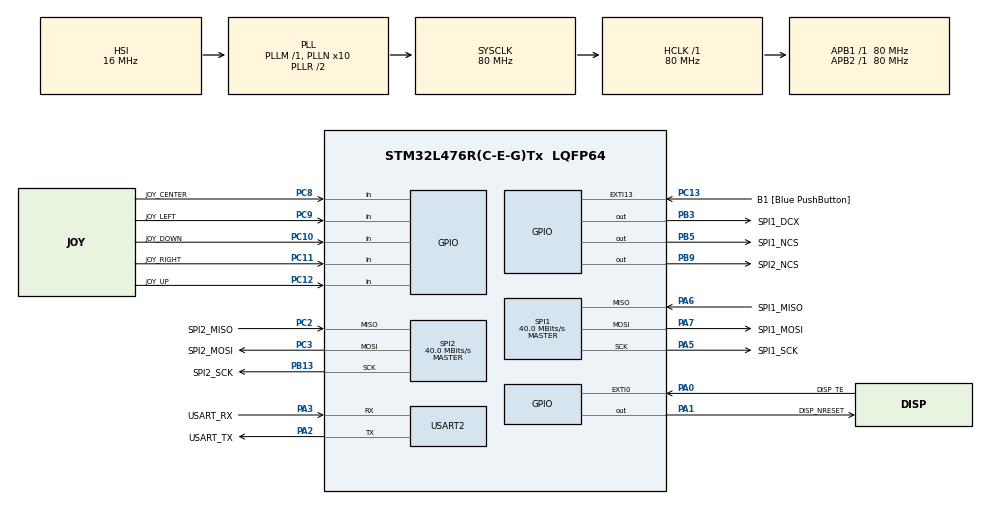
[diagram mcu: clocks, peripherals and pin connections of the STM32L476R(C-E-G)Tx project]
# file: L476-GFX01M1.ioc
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Dma.Request0=SPI1_TX
Dma.Request1=SPI2_RX
Dma.Request2=SPI2_TX
Dma.SPI1_TX.0.Direction=DMA_MEMORY_TO_PERIPH
Dma.SPI1_TX.0.Instance=DMA1_Channel3
Dma.SPI1_TX.0.MemDataAlignment=DMA_MDATAALIGN_HALFWORD
Dma.SPI1_TX.0.MemInc=DMA_MINC_ENABLE
Dma.SPI1_TX.0.Mode=DMA_NORMAL
Dma.SPI1_TX.0.PeriphDataAlignment=DMA_PDATAALIGN_HALFWORD
Dma.SPI1_TX.0.PeriphInc=DMA_PINC_DISABLE
Dma.SPI1_TX.0.Priority=DMA_PRIORITY_LOW
Dma.SPI2_RX.1.Direction=DMA_PERIPH_TO_MEMORY
Dma.SPI2_RX.1.Instance=DMA1_Channel4
Dma.SPI2_RX.1.MemDataAlignment=DMA_MDATAALIGN_BYTE
Dma.SPI2_RX.1.MemInc=DMA_MINC_ENABLE
Dma.SPI2_RX.1.Mode=DMA_NORMAL
Dma.SPI2_RX.1.PeriphDataAlignment=DMA_PDATAALIGN_BYTE
Dma.SPI2_RX.1.PeriphInc=DMA_PINC_DISABLE
Dma.SPI2_RX.1.Priority=DMA_PRIORITY_LOW
Dma.SPI2_TX.2.Direction=DMA_MEMORY_TO_PERIPH
Dma.SPI2_TX.2.Instance=DMA1_Channel5
Dma.SPI2_TX.2.MemDataAlignment=DMA_MDATAALIGN_BYTE
Dma.SPI2_TX.2.MemInc=DMA_MINC_ENABLE
Dma.SPI2_TX.2.Mode=DMA_NORMAL
Dma.SPI2_TX.2.PeriphDataAlignment=DMA_PDATAALIGN_BYTE
Dma.SPI2_TX.2.PeriphInc=DMA_PINC_DISABLE
Dma.SPI2_TX.2.Priority=DMA_PRIORITY_LOW
Mcu.Family=STM32L4
Mcu.Name=STM32L476R(C-E-G)Tx
Mcu.Package=LQFP64
NVIC.DMA1_Channel3_IRQn=true\:0\:0\:false\:false\:true\:false\:true
NVIC.DMA1_Channel4_IRQn=true\:0\:0\:false\:false\:true\:false\:true
NVIC.DMA1_Channel5_IRQn=true\:0\:0\:false\:false\:true\:false\:true
NVIC.EXTI0_IRQn=true\:1\:0\:true\:false\:true\:true\:true
NVIC.PriorityGroup=NVIC_PRIORITYGROUP_4
NVIC.SPI1_IRQn=true\:0\:0\:false\:false\:true\:true\:true
NVIC.SPI2_IRQn=true\:0\:0\:false\:false\:true\:true\:true
PA0.GPIO_Label=DISP_TE
PA0.Signal=GPXTI0
PA1.GPIO_Label=DISP_NRESET
PA1.GPIO_PuPd=GPIO_PULLUP
PA1.GPIO_Speed=GPIO_SPEED_FREQ_HIGH
PA1.PinState=GPIO_PIN_SET
PA1.Signal=GPIO_Output
PA13\ (JTMS-SWDIO).GPIO_Label=TMS
PA13\ (JTMS-SWDIO).Mode=Serial_Wire
PA13\ (JTMS-SWDIO).Signal=SYS_JTMS-SWDIO
PA14\ (JTCK-SWCLK).GPIO_Label=TCK
PA14\ (JTCK-SWCLK).Mode=Serial_Wire
PA14\ (JTCK-SWCLK).Signal=SYS_JTCK-SWCLK
PA2.GPIO_Label=USART_TX
PA2.GPIO_Mode=GPIO_MODE_AF_PP
PA2.GPIO_PuPd=GPIO_NOPULL
PA2.GPIO_Speed=GPIO_SPEED_FREQ_VERY_HIGH
PA2.Mode=Asynchronous
PA2.Signal=USART2_TX
PA3.GPIO_Label=USART_RX
PA3.GPIO_Mode=GPIO_MODE_AF_PP
PA3.GPIO_PuPd=GPIO_NOPULL
PA3.GPIO_Speed=GPIO_SPEED_FREQ_VERY_HIGH
PA3.Mode=Asynchronous
PA3.Signal=USART2_RX
PA5.GPIO_Label=SPI1_SCK
PA5.GPIO_Speed=GPIO_SPEED_FREQ_HIGH
PA5.Mode=Full_Duplex_Master
PA5.Signal=SPI1_SCK
PA6.GPIO_Label=SPI1_MISO
PA6.GPIO_Speed=GPIO_SPEED_FREQ_HIGH
PA6.Mode=Full_Duplex_Master
PA6.Signal=SPI1_MISO
PA7.GPIO_Label=SPI1_MOSI
PA7.GPIO_Speed=GPIO_SPEED_FREQ_HIGH
PA7.Mode=Full_Duplex_Master
PA7.Signal=SPI1_MOSI
PB13.GPIO_Label=SPI2_SCK
PB13.GPIO_Speed=GPIO_SPEED_FREQ_HIGH
PB13.Mode=Full_Duplex_Master
PB13.Signal=SPI2_SCK
PB3\ (JTDO-TRACESWO).GPIO_Label=SPI1_DCX
PB3\ (JTDO-TRACESWO).GPIO_Speed=GPIO_SPEED_FREQ_HIGH
PB3\ (JTDO-TRACESWO).Signal=GPIO_Output
PB5.GPIO_Label=SPI1_NCS
PB5.GPIO_PuPd=GPIO_PULLUP
PB5.GPIO_Speed=GPIO_SPEED_FREQ_HIGH
PB5.PinState=GPIO_PIN_SET
PB5.Signal=GPIO_Output
PB9.GPIO_Label=SPI2_NCS
PB9.GPIO_PuPd=GPIO_PULLUP
PB9.GPIO_Speed=GPIO_SPEED_FREQ_HIGH
PB9.PinState=GPIO_PIN_SET
PB9.Signal=GPIO_Output
PC10.GPIO_Label=JOY_DOWN
PC10.Signal=GPIO_Input
PC11.GPIO_Label=JOY_RIGHT
PC11.Signal=GPIO_Input
PC12.GPIO_Label=JOY_UP
PC12.Signal=GPIO_Input
PC13.GPIO_Label=B1 [Blue PushButton]
PC13.GPIO_ModeDefaultEXTI=GPIO_MODE_IT_FALLING
PC13.GPIO_PuPd=GPIO_NOPULL
PC13.Signal=GPXTI13
PC14-OSC32_IN\ (PC14).Mode=LSE-External-Oscillator
PC14-OSC32_IN\ (PC14).Signal=RCC_OSC32_IN
PC15-OSC32_OUT\ (PC15).Mode=LSE-External-Oscillator
PC15-OSC32_OUT\ (PC15).Signal=RCC_OSC32_OUT
PC2.GPIO_Label=SPI2_MISO
PC2.GPIO_Speed=GPIO_SPEED_FREQ_HIGH
PC2.Mode=Full_Duplex_Master
PC2.Signal=SPI2_MISO
PC3.GPIO_Label=SPI2_MOSI
PC3.GPIO_Speed=GPIO_SPEED_FREQ_HIGH
PC3.Mode=Full_Duplex_Master
PC3.Signal=SPI2_MOSI
PC8.GPIO_Label=JOY_CENTER
PC8.Signal=GPIO_Input
PC9.GPIO_Label=JOY_LEFT
PC9.Signal=GPIO_Input
PH0-OSC_IN\ (PH0).Signal=RCC_OSC_IN
PH1-OSC_OUT\ (PH1).Signal=RCC_OSC_OUT
ProjectManager.HeapSize=0x200
ProjectManager.StackSize=0x400
ProjectManager.TargetToolchain=STM32CubeIDE
RCC.ADCFreq_Value=64000000
RCC.AHBFreq_Value=80000000
RCC.APB1Freq_Value=80000000
RCC.APB1TimFreq_Value=80000000
RCC.APB2Freq_Value=80000000
RCC.APB2TimFreq_Value=80000000
RCC.CortexFreq_Value=80000000
RCC.HCLKFreq_Value=80000000
RCC.HSE_VALUE=8000000
RCC.HSI_VALUE=16000000
RCC.MSI_VALUE=4000000
RCC.PLLN=10
RCC.PLLSourceVirtual=RCC_PLLSOURCE_HSI
RCC.PREFETCH_ENABLE=1
RCC.SYSCLKFreq_VALUE=80000000
RCC.SYSCLKSource=RCC_SYSCLKSOURCE_PLLCLK
RCC.USBFreq_Value=64000000
RCC.VCOOutputFreq_Value=160000000
SPI1.CalculateBaudRate=40.0 MBits/s
SPI1.DataSize=SPI_DATASIZE_8BIT
SPI1.Direction=SPI_DIRECTION_2LINES
SPI1.Mode=SPI_MODE_MASTER
SPI1.NSSPMode=SPI_NSS_PULSE_DISABLE
SPI1.VirtualType=VM_MASTER
SPI2.CalculateBaudRate=40.0 MBits/s
SPI2.DataSize=SPI_DATASIZE_8BIT
SPI2.Direction=SPI_DIRECTION_2LINES
SPI2.Mode=SPI_MODE_MASTER
SPI2.NSSPMode=SPI_NSS_PULSE_DISABLE
SPI2.VirtualType=VM_MASTER
USART2.VirtualMode-Asynchronous=VM_ASYNC
VP_CRC_VS_CRC.Mode=CRC_Activate
board=NUCLEO-L476RG

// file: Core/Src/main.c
/* USER CODE BEGIN Header */
/**
  ******************************************************************************
  * @file           : main.c
  * @brief          : Main program body
  ******************************************************************************
  * @attention
  *
  * <h2><center>&copy; Copyright (c) 2020 STMicroelectronics.
  * All rights reserved.</center></h2>
  *
  * This software component is licensed by ST under BSD 3-Clause license,
  * the "License"; You may not use this file except in compliance with the
  * License. You may obtain a copy of the License at:
  *                        opensource.org/licenses/BSD-3-Clause
  *
  ******************************************************************************
  */
/* USER CODE END Header */
#include "main.h"

/* USER CODE BEGIN Includes */
#include "app_display.h"
/* USER CODE END Includes */

CRC_HandleTypeDef hcrc;

SPI_HandleTypeDef hspi1;
SPI_HandleTypeDef hspi2;
DMA_HandleTypeDef hdma_spi1_tx;
DMA_HandleTypeDef hdma_spi2_rx;
DMA_HandleTypeDef hdma_spi2_tx;

UART_HandleTypeDef huart2;

void SystemClock_Config(void);
static void MX_GPIO_Init(void);
static void MX_DMA_Init(void);
static void MX_USART2_UART_Init(void);
static void MX_SPI1_Init(void);
static void MX_SPI2_Init(void);
static void MX_CRC_Init(void);

int main(void)
{

  /* MCU Configuration--------------------------------------------------------*/

  /* Reset of all peripherals, Initializes the Flash interface and the Systick. */
  HAL_Init();

  /* Configure the system clock */
  SystemClock_Config();

  /* Initialize all configured peripherals */
  MX_GPIO_Init();
  MX_DMA_Init();
  MX_USART2_UART_Init();
  MX_SPI1_Init();
  MX_SPI2_Init();
  MX_CRC_Init();
  /* USER CODE BEGIN 2 */
  MX_DISPLAY_Init();
  /* USER CODE END 2 */

  /* Infinite loop */
  while (1)
  {

    /* USER CODE BEGIN 3 */
  	MX_DISPLAY_Process();
  }
  /* USER CODE END 3 */
}

void SystemClock_Config(void)
{
  RCC_OscInitTypeDef RCC_OscInitStruct = {0};
  RCC_ClkInitTypeDef RCC_ClkInitStruct = {0};
  RCC_PeriphCLKInitTypeDef PeriphClkInit = {0};

  /** Initializes the RCC Oscillators according to the specified parameters
  * in the RCC_OscInitTypeDef structure.
  */
  RCC_OscInitStruct.OscillatorType = RCC_OSCILLATORTYPE_HSI;
  RCC_OscInitStruct.HSIState = RCC_HSI_ON;
  RCC_OscInitStruct.HSICalibrationValue = RCC_HSICALIBRATION_DEFAULT;
  RCC_OscInitStruct.PLL.PLLState = RCC_PLL_ON;
  RCC_OscInitStruct.PLL.PLLSource = RCC_PLLSOURCE_HSI;
  RCC_OscInitStruct.PLL.PLLM = 1;
  RCC_OscInitStruct.PLL.PLLN = 10;
  RCC_OscInitStruct.PLL.PLLP = RCC_PLLP_DIV7;
  RCC_OscInitStruct.PLL.PLLQ = RCC_PLLQ_DIV2;
  RCC_OscInitStruct.PLL.PLLR = RCC_PLLR_DIV2;
  if (HAL_RCC_OscConfig(&RCC_OscInitStruct) != HAL_OK)
  {
    Error_Handler();
  }
  /** Initializes the CPU, AHB and APB buses clocks
  */
  RCC_ClkInitStruct.ClockType = RCC_CLOCKTYPE_HCLK|RCC_CLOCKTYPE_SYSCLK
                              |RCC_CLOCKTYPE_PCLK1|RCC_CLOCKTYPE_PCLK2;
  RCC_ClkInitStruct.SYSCLKSource = RCC_SYSCLKSOURCE_PLLCLK;
  RCC_ClkInitStruct.AHBCLKDivider = RCC_SYSCLK_DIV1;
  RCC_ClkInitStruct.APB1CLKDivider = RCC_HCLK_DIV1;
  RCC_ClkInitStruct.APB2CLKDivider = RCC_HCLK_DIV1;

  if (HAL_RCC_ClockConfig(&RCC_ClkInitStruct, FLASH_LATENCY_4) != HAL_OK)
  {
    Error_Handler();
  }
  PeriphClkInit.PeriphClockSelection = RCC_PERIPHCLK_USART2;
  PeriphClkInit.Usart2ClockSelection = RCC_USART2CLKSOURCE_PCLK1;
  if (HAL_RCCEx_PeriphCLKConfig(&PeriphClkInit) != HAL_OK)
  {
    Error_Handler();
  }
  /** Configure the main internal regulator output voltage
  */
  if (HAL_PWREx_ControlVoltageScaling(PWR_REGULATOR_VOLTAGE_SCALE1) != HAL_OK)
  {
    Error_Handler();
  }
}

static void MX_CRC_Init(void)
{

  hcrc.Instance = CRC;
  hcrc.Init.DefaultPolynomialUse = DEFAULT_POLYNOMIAL_ENABLE;
  hcrc.Init.DefaultInitValueUse = DEFAULT_INIT_VALUE_ENABLE;
  hcrc.Init.InputDataInversionMode = CRC_INPUTDATA_INVERSION_NONE;
  hcrc.Init.OutputDataInversionMode = CRC_OUTPUTDATA_INVERSION_DISABLE;
  hcrc.InputDataFormat = CRC_INPUTDATA_FORMAT_BYTES;
  if (HAL_CRC_Init(&hcrc) != HAL_OK)
  {
    Error_Handler();
  }

}

static void MX_SPI1_Init(void)
{

  /* SPI1 parameter configuration*/
  hspi1.Instance = SPI1;
  hspi1.Init.Mode = SPI_MODE_MASTER;
  hspi1.Init.Direction = SPI_DIRECTION_2LINES;
  hspi1.Init.DataSize = SPI_DATASIZE_8BIT;
  hspi1.Init.CLKPolarity = SPI_POLARITY_LOW;
  hspi1.Init.CLKPhase = SPI_PHASE_1EDGE;
  hspi1.Init.NSS = SPI_NSS_SOFT;
  hspi1.Init.BaudRatePrescaler = SPI_BAUDRATEPRESCALER_2;
  hspi1.Init.FirstBit = SPI_FIRSTBIT_MSB;
  hspi1.Init.TIMode = SPI_TIMODE_DISABLE;
  hspi1.Init.CRCCalculation = SPI_CRCCALCULATION_DISABLE;
  hspi1.Init.CRCPolynomial = 7;
  hspi1.Init.CRCLength = SPI_CRC_LENGTH_DATASIZE;
  hspi1.Init.NSSPMode = SPI_NSS_PULSE_DISABLE;
  if (HAL_SPI_Init(&hspi1) != HAL_OK)
  {
    Error_Handler();
  }

}

static void MX_SPI2_Init(void)
{

  /* SPI2 parameter configuration*/
  hspi2.Instance = SPI2;
  hspi2.Init.Mode = SPI_MODE_MASTER;
  hspi2.Init.Direction = SPI_DIRECTION_2LINES;
  hspi2.Init.DataSize = SPI_DATASIZE_8BIT;
  hspi2.Init.CLKPolarity = SPI_POLARITY_LOW;
  hspi2.Init.CLKPhase = SPI_PHASE_1EDGE;
  hspi2.Init.NSS = SPI_NSS_SOFT;
  hspi2.Init.BaudRatePrescaler = SPI_BAUDRATEPRESCALER_2;
  hspi2.Init.FirstBit = SPI_FIRSTBIT_MSB;
  hspi2.Init.TIMode = SPI_TIMODE_DISABLE;
  hspi2.Init.CRCCalculation = SPI_CRCCALCULATION_DISABLE;
  hspi2.Init.CRCPolynomial = 7;
  hspi2.Init.CRCLength = SPI_CRC_LENGTH_DATASIZE;
  hspi2.Init.NSSPMode = SPI_NSS_PULSE_DISABLE;
  if (HAL_SPI_Init(&hspi2) != HAL_OK)
  {
    Error_Handler();
  }

}

static void MX_USART2_UART_Init(void)
{

  huart2.Instance = USART2;
  huart2.Init.BaudRate = 115200;
  huart2.Init.WordLength = UART_WORDLENGTH_8B;
  huart2.Init.StopBits = UART_STOPBITS_1;
  huart2.Init.Parity = UART_PARITY_NONE;
  huart2.Init.Mode = UART_MODE_TX_RX;
  huart2.Init.HwFlowCtl = UART_HWCONTROL_NONE;
  huart2.Init.OverSampling = UART_OVERSAMPLING_16;
  huart2.Init.OneBitSampling = UART_ONE_BIT_SAMPLE_DISABLE;
  huart2.AdvancedInit.AdvFeatureInit = UART_ADVFEATURE_NO_INIT;
  if (HAL_UART_Init(&huart2) != HAL_OK)
  {
    Error_Handler();
  }

}

static void MX_DMA_Init(void)
{

  /* DMA controller clock enable */
  __HAL_RCC_DMA1_CLK_ENABLE();

  /* DMA interrupt init */
  /* DMA1_Channel3_IRQn interrupt configuration */
  HAL_NVIC_SetPriority(DMA1_Channel3_IRQn, 0, 0);
  HAL_NVIC_EnableIRQ(DMA1_Channel3_IRQn);
  /* DMA1_Channel4_IRQn interrupt configuration */
  HAL_NVIC_SetPriority(DMA1_Channel4_IRQn, 0, 0);
  HAL_NVIC_EnableIRQ(DMA1_Channel4_IRQn);
  /* DMA1_Channel5_IRQn interrupt configuration */
  HAL_NVIC_SetPriority(DMA1_Channel5_IRQn, 0, 0);
  HAL_NVIC_EnableIRQ(DMA1_Channel5_IRQn);

}

static void MX_GPIO_Init(void)
{
  GPIO_InitTypeDef GPIO_InitStruct = {0};

  /* GPIO Ports Clock Enable */
  __HAL_RCC_GPIOC_CLK_ENABLE();
  __HAL_RCC_GPIOH_CLK_ENABLE();
  __HAL_RCC_GPIOA_CLK_ENABLE();
  __HAL_RCC_GPIOB_CLK_ENABLE();

  /*Configure GPIO pin Output Level */
  HAL_GPIO_WritePin(DISP_NRESET_GPIO_Port, DISP_NRESET_Pin, GPIO_PIN_SET);

  /*Configure GPIO pin Output Level */
  HAL_GPIO_WritePin(SPI1_DCX_GPIO_Port, SPI1_DCX_Pin, GPIO_PIN_RESET);

  /*Configure GPIO pin Output Level */
  HAL_GPIO_WritePin(GPIOB, SPI1_NCS_Pin|SPI2_NCS_Pin, GPIO_PIN_SET);

  /*Configure GPIO pin : B1_Pin */
  GPIO_InitStruct.Pin = B1_Pin;
  GPIO_InitStruct.Mode = GPIO_MODE_IT_FALLING;
  GPIO_InitStruct.Pull = GPIO_NOPULL;
  HAL_GPIO_Init(B1_GPIO_Port, &GPIO_InitStruct);

  /*Configure GPIO pin : DISP_TE_Pin */
  GPIO_InitStruct.Pin = DISP_TE_Pin;
  GPIO_InitStruct.Mode = GPIO_MODE_IT_RISING;
  GPIO_InitStruct.Pull = GPIO_NOPULL;
  HAL_GPIO_Init(DISP_TE_GPIO_Port, &GPIO_InitStruct);

  /*Configure GPIO pin : DISP_NRESET_Pin */
  GPIO_InitStruct.Pin = DISP_NRESET_Pin;
  GPIO_InitStruct.Mode = GPIO_MODE_OUTPUT_PP;
  GPIO_InitStruct.Pull = GPIO_PULLUP;
  GPIO_InitStruct.Speed = GPIO_SPEED_FREQ_HIGH;
  HAL_GPIO_Init(DISP_NRESET_GPIO_Port, &GPIO_InitStruct);

  /*Configure GPIO pins : JOY_CENTER_Pin JOY_LEFT_Pin JOY_DOWN_Pin JOY_RIGHT_Pin
                           JOY_UP_Pin */
  GPIO_InitStruct.Pin = JOY_CENTER_Pin|JOY_LEFT_Pin|JOY_DOWN_Pin|JOY_RIGHT_Pin
                          |JOY_UP_Pin;
  GPIO_InitStruct.Mode = GPIO_MODE_INPUT;
  GPIO_InitStruct.Pull = GPIO_NOPULL;
  HAL_GPIO_Init(GPIOC, &GPIO_InitStruct);

  /*Configure GPIO pin : SPI1_DCX_Pin */
  GPIO_InitStruct.Pin = SPI1_DCX_Pin;
  GPIO_InitStruct.Mode = GPIO_MODE_OUTPUT_PP;
  GPIO_InitStruct.Pull = GPIO_NOPULL;
  GPIO_InitStruct.Speed = GPIO_SPEED_FREQ_HIGH;
  HAL_GPIO_Init(SPI1_DCX_GPIO_Port, &GPIO_InitStruct);

  /*Configure GPIO pins : SPI1_NCS_Pin SPI2_NCS_Pin */
  GPIO_InitStruct.Pin = SPI1_NCS_Pin|SPI2_NCS_Pin;
  GPIO_InitStruct.Mode = GPIO_MODE_OUTPUT_PP;
  GPIO_InitStruct.Pull = GPIO_PULLUP;
  GPIO_InitStruct.Speed = GPIO_SPEED_FREQ_HIGH;
  HAL_GPIO_Init(GPIOB, &GPIO_InitStruct);

  /* EXTI interrupt init*/
  HAL_NVIC_SetPriority(EXTI0_IRQn, 1, 0);
  HAL_NVIC_EnableIRQ(EXTI0_IRQn);

}

void Error_Handler(void)
{
}

/************************ (C) COPYRIGHT STMicroelectronics *****END OF FILE****/
